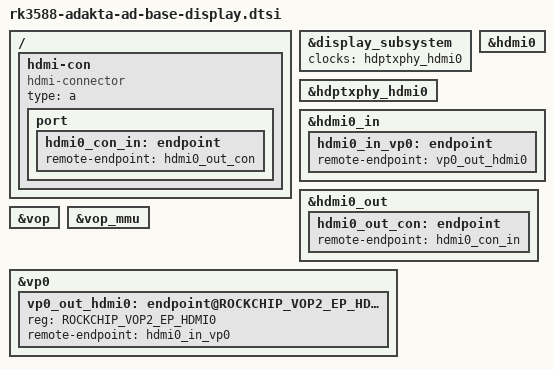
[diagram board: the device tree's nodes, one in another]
// SPDX-License-Identifier: (GPL-2.0+ OR MIT)
/*
 * Copyright (c) 2024 Adakta, Ltd.
 *
 */

/ {
	hdmi-con {
		compatible = "hdmi-connector";
		type = "a";

		port {
			hdmi0_con_in: endpoint {
				remote-endpoint = <&hdmi0_out_con>;
			};
		};
	};
};

&display_subsystem {
	clocks = <&hdptxphy_hdmi0>;
	clock-names = "hdmi0_phy_pll";
};

&hdptxphy_hdmi0 {
	status = "okay";
};

&hdmi0 {
	status = "okay";
};

&hdmi0_in {
	hdmi0_in_vp0: endpoint {
		remote-endpoint = <&vp0_out_hdmi0>;
	};
};

&hdmi0_out {
	hdmi0_out_con: endpoint {
		remote-endpoint = <&hdmi0_con_in>;
	};
};

&vop {
	status = "okay";
};

&vop_mmu {
	status = "okay";
};

&vp0 {
	vp0_out_hdmi0: endpoint@ROCKCHIP_VOP2_EP_HDMI0 {
		reg = <ROCKCHIP_VOP2_EP_HDMI0>;
		remote-endpoint = <&hdmi0_in_vp0>;
	};
};
